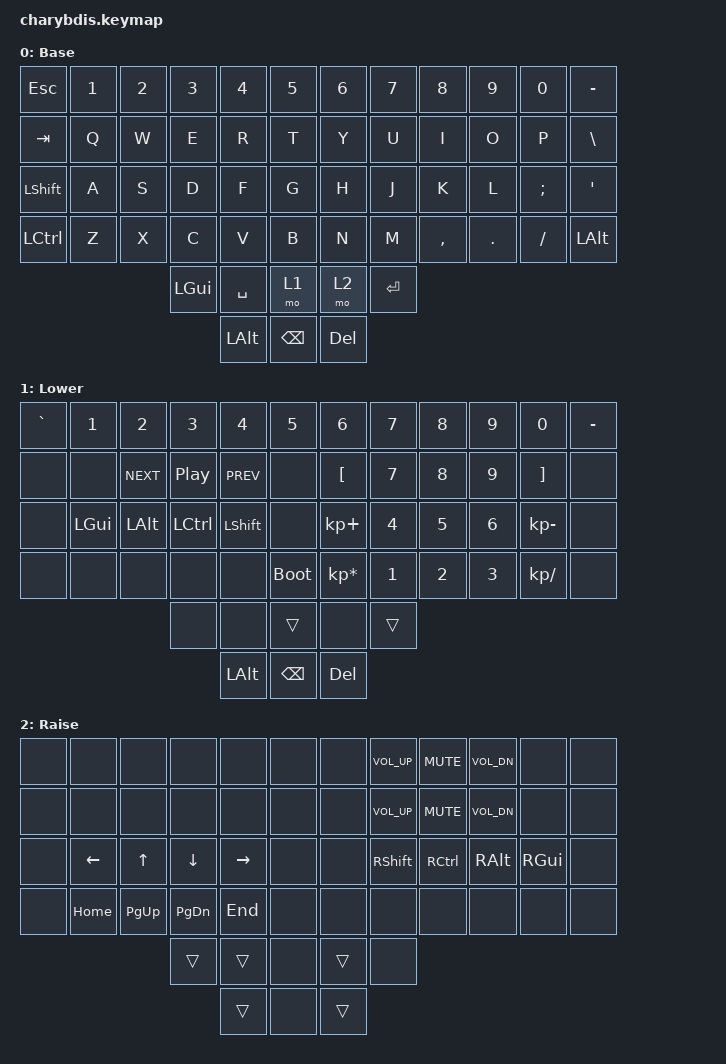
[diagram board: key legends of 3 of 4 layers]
#include <behaviors.dtsi>
#include <dt-bindings/zmk/keys.h>
#include <dt-bindings/zmk/bt.h>
#include <dt-bindings/zmk/mouse.h>

/ {
    keymap {
        compatible = "zmk,keymap";

        Base {
            bindings = <
            &kp ESC    &kp N1  &kp N2  &kp N3      &kp N4      &kp N5          &kp N6    &kp N7      &kp N8    &kp N9      &kp N0    &kp MINUS               
            &kp TAB    &kp Q   &kp W   &kp E       &kp R       &kp T           &kp Y     &kp U       &kp I     &kp O       &kp P     &kp BACKSLASH 
            &kp LSHIFT &kp A   &kp S   &kp D       &kp F       &kp G           &kp H     &kp J       &kp K     &kp L       &kp SEMI  &kp APOS
            &kp LCTRL  &kp Z   &kp X   &kp C       &kp V       &kp B           &kp N     &kp M       &kp COMMA &kp DOT     &kp SLASH &kp LALT
                                       &kp LGUI    &kp SPACE   &mo 1           &mo 2     &kp RET
                                                   &kp LALT    &kp BACKSPACE   &kp DEL
            >;
        };

        Lower {
            bindings = <
            &kp GRAVE &kp N1  &kp N2  &kp N3      &kp N4      &kp N5          &kp N6    &kp N7      &kp N8    &kp N9      &kp N0    &kp MINUS               
            &none    &none      &kp C_NEXT  &kp C_PP    &kp C_PREV  &none                      &kp LBKT     &kp N7  &kp N8  &kp N9      &kp RBKT    &none
            &none    &kp LGUI   &kp LALT    &kp LCTRL   &kp LSHIFT  &none                   &kp KP_PLUS     &kp N4  &kp N5  &kp N6  &kp KP_MINUS    &none
            &none    &none      &none       &none       &none       &bootloader         &kp KP_MULTIPLY     &kp N1  &kp N2  &kp N3  &kp KP_SLASH    &none
                                            &none       &none       &trans                        &none     &trans
                                                   &kp LALT    &kp BACKSPACE   &kp DEL
            >;
        };

        Raise {
            bindings = <
            &none    &none      &none       &none       &none       &none            &none  &kp C_VOL_UP    &kp C_MUTE  &kp C_VOL_DN       &none    &none
            &none    &none      &none       &none       &none       &none            &none  &kp C_VOL_UP    &kp C_MUTE  &kp C_VOL_DN       &none    &none
            &none    &kp LEFT   &kp UP      &kp DOWN    &kp RIGHT   &none            &none    &kp RSHIFT     &kp RCTRL      &kp RALT    &kp RGUI    &none
            &none    &kp HOME   &kp PG_UP   &kp PG_DN   &kp END     &none            &none         &none         &none         &none       &none    &none
                                            &trans      &trans      &none           &trans         &none
                                            			&trans      &none           &trans         
            >;
        };

        Pointer {
            bindings = <
            &bootloader &none       &none       &none       &none       &none              &none        &none      &none      &none       &none    &bootloader
            &bootloader &none       &none       &none       &none       &none              &none        &none      &none      &none       &none    &bootloader
            &none       &kp LGUI    &kp LALT    &kp LCTRL   &kp LSHIFT  &none              &none   &kp RSHIFT  &kp RCTRL   &kp RALT    &kp RGUI          &none
            &none       &none       &none       &none       &none       &none              &none        &none      &none      &none       &none          &none
                                    &mkp MB2    &mkp MB1    &mkp MB3                    &mkp MB3     &mkp MB1
            >;
        };
    };
};
